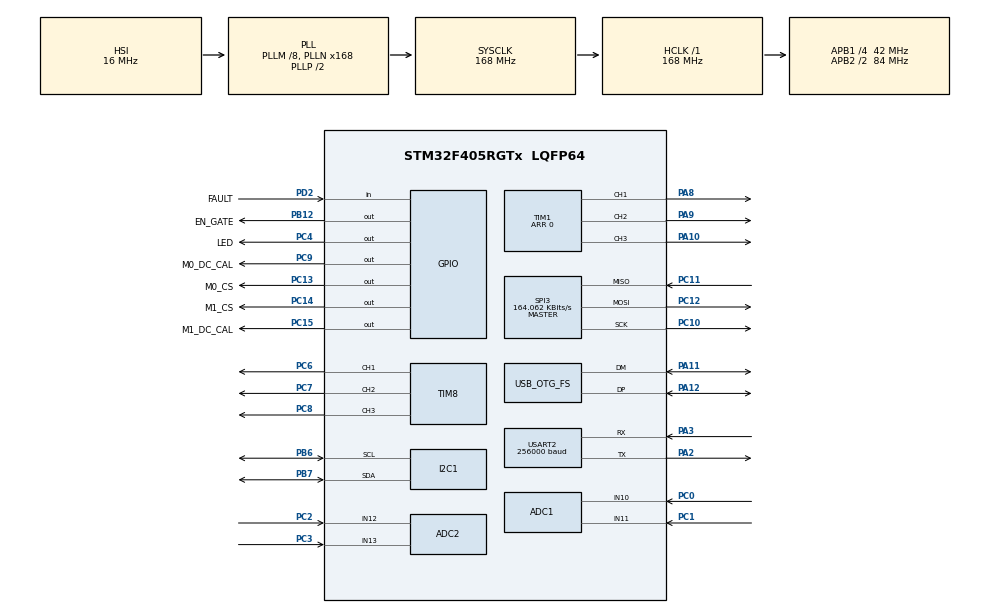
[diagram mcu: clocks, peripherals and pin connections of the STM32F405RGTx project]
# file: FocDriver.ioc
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ADC1.Channel-0\#ChannelRegularConversion=ADC_CHANNEL_10
ADC1.Channel-1\#ChannelInjectedConversion=ADC_CHANNEL_10
ADC1.Channel-2\#ChannelInjectedConversion=ADC_CHANNEL_10
ADC1.Channel-3\#ChannelRegularConversion=ADC_CHANNEL_10
ADC1.ExternalTrigConv=ADC_EXTERNALTRIGCONV_T8_TRGO
ADC1.ExternalTrigInjecConv=ADC_EXTERNALTRIGINJECCONV_T8_CC4
ADC1.InjNumberOfConversion=2
ADC1.InjectedOffset-1\#ChannelInjectedConversion=0
ADC1.InjectedOffset-2\#ChannelInjectedConversion=0
ADC1.InjectedRank-1\#ChannelInjectedConversion=1
ADC1.InjectedRank-2\#ChannelInjectedConversion=2
ADC1.NbrOfConversion=2
ADC1.NbrOfConversionFlag=1
ADC1.Rank-0\#ChannelRegularConversion=1
ADC1.Rank-3\#ChannelRegularConversion=2
ADC1.SamplingTime-0\#ChannelRegularConversion=ADC_SAMPLETIME_3CYCLES
ADC1.SamplingTime-1\#ChannelInjectedConversion=ADC_SAMPLETIME_3CYCLES
ADC1.SamplingTime-2\#ChannelInjectedConversion=ADC_SAMPLETIME_3CYCLES
ADC1.SamplingTime-3\#ChannelRegularConversion=ADC_SAMPLETIME_3CYCLES
ADC1.master=1
ADC2.Channel-0\#ChannelRegularConversion=ADC_CHANNEL_13
ADC2.Channel-1\#ChannelRegularConversion=ADC_CHANNEL_12
ADC2.Channel-5\#ChannelInjectedConversion=ADC_CHANNEL_13
ADC2.Channel-6\#ChannelInjectedConversion=ADC_CHANNEL_12
ADC2.DiscontinuousConvMode=DISABLE
ADC2.ExternalTrigConv=ADC_EXTERNALTRIGCONV_T8_TRGO
ADC2.ExternalTrigInjecConv=ADC_EXTERNALTRIGINJECCONV_T8_CC4
ADC2.InjNumberOfConversion=2
ADC2.InjectedOffset-5\#ChannelInjectedConversion=0
ADC2.InjectedOffset-6\#ChannelInjectedConversion=0
ADC2.InjectedRank-5\#ChannelInjectedConversion=1
ADC2.InjectedRank-6\#ChannelInjectedConversion=2
ADC2.NbrOfConversion=2
ADC2.NbrOfConversionFlag=1
ADC2.Rank-0\#ChannelRegularConversion=1
ADC2.Rank-1\#ChannelRegularConversion=2
ADC2.SamplingTime-0\#ChannelRegularConversion=ADC_SAMPLETIME_3CYCLES
ADC2.SamplingTime-1\#ChannelRegularConversion=ADC_SAMPLETIME_3CYCLES
ADC2.SamplingTime-5\#ChannelInjectedConversion=ADC_SAMPLETIME_3CYCLES
ADC2.SamplingTime-6\#ChannelInjectedConversion=ADC_SAMPLETIME_3CYCLES
ADC2.ScanConvMode=ENABLE
Dma.ADC2.2.Direction=DMA_PERIPH_TO_MEMORY
Dma.ADC2.2.FIFOMode=DMA_FIFOMODE_DISABLE
Dma.ADC2.2.Instance=DMA2_Stream2
Dma.ADC2.2.MemDataAlignment=DMA_MDATAALIGN_HALFWORD
Dma.ADC2.2.MemInc=DMA_MINC_ENABLE
Dma.ADC2.2.Mode=DMA_NORMAL
Dma.ADC2.2.PeriphDataAlignment=DMA_PDATAALIGN_HALFWORD
Dma.ADC2.2.PeriphInc=DMA_PINC_DISABLE
Dma.ADC2.2.Priority=DMA_PRIORITY_LOW
Dma.Request0=USART2_TX
Dma.Request1=USART2_RX
Dma.Request2=ADC2
Dma.USART2_RX.1.Direction=DMA_PERIPH_TO_MEMORY
Dma.USART2_RX.1.FIFOMode=DMA_FIFOMODE_DISABLE
Dma.USART2_RX.1.Instance=DMA1_Stream5
Dma.USART2_RX.1.MemDataAlignment=DMA_MDATAALIGN_BYTE
Dma.USART2_RX.1.MemInc=DMA_MINC_ENABLE
Dma.USART2_RX.1.Mode=DMA_NORMAL
Dma.USART2_RX.1.PeriphDataAlignment=DMA_PDATAALIGN_BYTE
Dma.USART2_RX.1.PeriphInc=DMA_PINC_DISABLE
Dma.USART2_RX.1.Priority=DMA_PRIORITY_LOW
Dma.USART2_TX.0.Direction=DMA_MEMORY_TO_PERIPH
Dma.USART2_TX.0.FIFOMode=DMA_FIFOMODE_DISABLE
Dma.USART2_TX.0.Instance=DMA1_Stream6
Dma.USART2_TX.0.MemDataAlignment=DMA_MDATAALIGN_BYTE
Dma.USART2_TX.0.MemInc=DMA_MINC_ENABLE
Dma.USART2_TX.0.Mode=DMA_NORMAL
Dma.USART2_TX.0.PeriphDataAlignment=DMA_PDATAALIGN_BYTE
Dma.USART2_TX.0.PeriphInc=DMA_PINC_DISABLE
Dma.USART2_TX.0.Priority=DMA_PRIORITY_LOW
I2C1.I2C_Mode=I2C_Fast
Mcu.Family=STM32F4
Mcu.Name=STM32F405RGTx
Mcu.Package=LQFP64
Mcu.UserConstants=TIM_PWM_FREQ,30000;TIM_CLK_MHZ,168
NVIC.ADC_IRQn=true\:0\:0\:false\:false\:true\:true\:true\:true
NVIC.DMA1_Stream5_IRQn=true\:0\:0\:false\:false\:true\:false\:true\:true
NVIC.DMA1_Stream6_IRQn=true\:0\:0\:false\:false\:true\:false\:true\:true
NVIC.DMA2_Stream2_IRQn=true\:0\:0\:false\:false\:true\:false\:true\:true
NVIC.OTG_FS_IRQn=true\:0\:0\:false\:false\:true\:false\:true\:true
NVIC.PriorityGroup=NVIC_PRIORITYGROUP_4
NVIC.TIM8_TRG_COM_TIM14_IRQn=true\:15\:0\:false\:false\:true\:false\:true\:true
NVIC.TimeBase=TIM8_TRG_COM_TIM14_IRQn
NVIC.TimeBaseIP=TIM14
NVIC.USART2_IRQn=true\:0\:0\:false\:false\:true\:true\:true\:true
PA10.Signal=S_TIM1_CH3
PA11.Mode=Device_Only
PA11.Signal=USB_OTG_FS_DM
PA12.Mode=Device_Only
PA12.Signal=USB_OTG_FS_DP
PA13.Mode=Serial_Wire
PA13.Signal=SYS_JTMS-SWDIO
PA14.Mode=Serial_Wire
PA14.Signal=SYS_JTCK-SWCLK
PA2.Mode=Asynchronous
PA2.Signal=USART2_TX
PA3.Mode=Asynchronous
PA3.Signal=USART2_RX
PA8.Signal=S_TIM1_CH1
PA9.Signal=S_TIM1_CH2
PB12.GPIO_Label=EN_GATE
PB12.Signal=GPIO_Output
PB6.Mode=I2C
PB6.Signal=I2C1_SCL
PB7.Mode=I2C
PB7.Signal=I2C1_SDA
PC0.Signal=ADCx_IN10
PC1.Signal=ADCx_IN11
PC10.Mode=Full_Duplex_Master
PC10.Signal=SPI3_SCK
PC11.Mode=Full_Duplex_Master
PC11.Signal=SPI3_MISO
PC12.Mode=Full_Duplex_Master
PC12.Signal=SPI3_MOSI
PC13-ANTI_TAMP.GPIO_Label=M0_CS
PC13-ANTI_TAMP.Signal=GPIO_Output
PC14-OSC32_IN.GPIO_Label=M1_CS
PC14-OSC32_IN.Signal=GPIO_Output
PC15-OSC32_OUT.GPIO_Label=M1_DC_CAL
PC15-OSC32_OUT.Signal=GPIO_Output
PC2.Signal=ADCx_IN12
PC3.Signal=ADCx_IN13
PC4.GPIO_Label=LED
PC4.PinState=GPIO_PIN_SET
PC4.Signal=GPIO_Output
PC6.Signal=S_TIM8_CH1
PC7.Signal=S_TIM8_CH2
PC8.Signal=S_TIM8_CH3
PC9.GPIO_Label=M0_DC_CAL
PC9.Signal=GPIO_Output
PD2.GPIO_Label=FAULT
PD2.GPIO_PuPd=GPIO_PULLUP
PD2.Signal=GPIO_Input
ProjectManager.HeapSize=0x400
ProjectManager.StackSize=0x400
ProjectManager.TargetToolchain=STM32CubeIDE
RCC.48MHZClocksFreq_Value=84000000
RCC.AHBFreq_Value=168000000
RCC.APB1CLKDivider=RCC_HCLK_DIV4
RCC.APB1Freq_Value=42000000
RCC.APB1TimFreq_Value=84000000
RCC.APB2CLKDivider=RCC_HCLK_DIV2
RCC.APB2Freq_Value=84000000
RCC.APB2TimFreq_Value=168000000
RCC.CortexFreq_Value=168000000
RCC.HCLKFreq_Value=168000000
RCC.HSE_VALUE=16000000
RCC.HSI_VALUE=16000000
RCC.LSE_VALUE=32768
RCC.PLLM=8
RCC.PLLN=168
RCC.PLLSourceVirtualString=RCC_PLLSOURCE_HSI
RCC.SYSCLKFreq_VALUE=168000000
RCC.SYSCLKSource=RCC_SYSCLKSOURCE_PLLCLK
RCC.VCOOutputFreq_Value=336000000
SH.ADCx_IN10.0=ADC1_IN10,IN10
SH.ADCx_IN11.0=ADC1_IN11,IN11
SH.ADCx_IN12.0=ADC2_IN12,IN12
SH.ADCx_IN13.0=ADC2_IN13,IN13
SH.S_TIM1_CH1.0=TIM1_CH1,PWM Generation1 CH1
SH.S_TIM1_CH2.0=TIM1_CH2,PWM Generation2 CH2
SH.S_TIM1_CH3.0=TIM1_CH3,PWM Generation3 CH3
SH.S_TIM8_CH1.0=TIM8_CH1,PWM Generation1 CH1
SH.S_TIM8_CH2.0=TIM8_CH2,PWM Generation2 CH2
SH.S_TIM8_CH3.0=TIM8_CH3,PWM Generation3 CH3
SPI3.BaudRatePrescaler=SPI_BAUDRATEPRESCALER_256
SPI3.CLKPhase=SPI_PHASE_2EDGE
SPI3.CalculateBaudRate=164.062 KBits/s
SPI3.DataSize=SPI_DATASIZE_16BIT
SPI3.Direction=SPI_DIRECTION_2LINES
SPI3.Mode=SPI_MODE_MASTER
SPI3.VirtualType=VM_MASTER
TIM1.AutoReloadPreload=TIM_AUTORELOAD_PRELOAD_ENABLE
TIM1.Channel-PWM\ Generation1\ CH1=TIM_CHANNEL_1
TIM1.Channel-PWM\ Generation2\ CH2=TIM_CHANNEL_2
TIM1.Channel-PWM\ Generation3\ CH3=TIM_CHANNEL_3
TIM1.CounterMode=TIM_COUNTERMODE_CENTERALIGNED1
TIM1.Period=0
TIM1.TIM_MasterOutputTrigger=TIM_TRGO_UPDATE
TIM8.AutoReloadPreload=TIM_AUTORELOAD_PRELOAD_ENABLE
TIM8.Channel-PWM\ Generation1\ CH1=TIM_CHANNEL_1
TIM8.Channel-PWM\ Generation2\ CH2=TIM_CHANNEL_2
TIM8.Channel-PWM\ Generation3\ CH3=TIM_CHANNEL_3
TIM8.Channel-PWM\ Generation4\ No\ Output=TIM_CHANNEL_4
TIM8.CounterMode=TIM_COUNTERMODE_CENTERALIGNED1
TIM8.OCMode_PWM-PWM\ Generation4\ No\ Output=TIM_OCMODE_PWM2
TIM8.OCPolarity_4=TIM_OCPOLARITY_HIGH
TIM8.Period=TIM_CLK_MHZ * 1000000 / TIM_PWM_FREQ / 2
TIM8.TIM_MasterOutputTrigger=TIM_TRGO_UPDATE
USART2.BaudRate=256000
USART2.VirtualMode=VM_ASYNC
USB_DEVICE.CLASS_NAME_FS=CDC
USB_DEVICE.VirtualMode-CDC_FS=Cdc
USB_DEVICE.VirtualModeFS=Cdc_FS
USB_OTG_FS.VirtualMode=Device_Only
VP_SYS_VS_tim14.Mode=TIM14
VP_TIM8_VS_no_output4.Mode=PWM Generation4 No Output
VP_USB_DEVICE_VS_USB_DEVICE_CDC_FS.Mode=CDC_FS
board=custom

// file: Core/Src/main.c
/* USER CODE BEGIN Header */
/**
  ******************************************************************************
  * @file           : main.c
  * @brief          : Main program body
  ******************************************************************************
  * @attention
  *
  * Copyright (c) 2023 STMicroelectronics.
  * All rights reserved.
  *
  * This software is licensed under terms that can be found in the LICENSE file
  * in the root directory of this software component.
  * If no LICENSE file comes with this software, it is provided AS-IS.
  *
  ******************************************************************************
  */
/* USER CODE END Header */
#include "main.h"
#include "adc.h"
#include "dma.h"
#include "i2c.h"
#include "spi.h"
#include "tim.h"
#include "usart.h"
#include "gpio.h"

/* USER CODE BEGIN Includes */
#include "common_inc.h"
#include "stdio.h"
/* USER CODE END Includes */

void SystemClock_Config(void);

/* USER CODE BEGIN 0 */
//ccmram char test[1024];
/* USER CODE END 0 */

int main(void)
{
  /* USER CODE BEGIN 1 */
//  for (int i = 0; i < sizeof(test); ++i, test[i] = 0);
  /* USER CODE END 1 */

  /* MCU Configuration--------------------------------------------------------*/

  /* Reset of all peripherals, Initializes the Flash interface and the Systick. */
  HAL_Init();

  /* Configure the system clock */
  SystemClock_Config();

  /* Initialize all configured peripherals */
  MX_GPIO_Init();
  MX_DMA_Init();
  MX_USART2_UART_Init();
  MX_SPI3_Init();
  MX_TIM1_Init();
  MX_I2C1_Init();
  MX_TIM8_Init();
  MX_ADC1_Init();
  MX_ADC2_Init();
  /* USER CODE BEGIN 2 */
  Main();
  /* USER CODE END 2 */

  /* Infinite loop */
    while (1) {

    }
}

void SystemClock_Config(void)
{
  RCC_OscInitTypeDef RCC_OscInitStruct = {0};
  RCC_ClkInitTypeDef RCC_ClkInitStruct = {0};

  /** Configure the main internal regulator output voltage
  */
  __HAL_RCC_PWR_CLK_ENABLE();
  __HAL_PWR_VOLTAGESCALING_CONFIG(PWR_REGULATOR_VOLTAGE_SCALE1);

  /** Initializes the RCC Oscillators according to the specified parameters
  * in the RCC_OscInitTypeDef structure.
  */
  RCC_OscInitStruct.OscillatorType = RCC_OSCILLATORTYPE_HSI;
  RCC_OscInitStruct.HSIState = RCC_HSI_ON;
  RCC_OscInitStruct.HSICalibrationValue = RCC_HSICALIBRATION_DEFAULT;
  RCC_OscInitStruct.PLL.PLLState = RCC_PLL_ON;
  RCC_OscInitStruct.PLL.PLLSource = RCC_PLLSOURCE_HSI;
  RCC_OscInitStruct.PLL.PLLM = 8;
  RCC_OscInitStruct.PLL.PLLN = 168;
  RCC_OscInitStruct.PLL.PLLP = RCC_PLLP_DIV2;
  RCC_OscInitStruct.PLL.PLLQ = 4;
  if (HAL_RCC_OscConfig(&RCC_OscInitStruct) != HAL_OK)
  {
    Error_Handler();
  }

  /** Initializes the CPU, AHB and APB buses clocks
  */
  RCC_ClkInitStruct.ClockType = RCC_CLOCKTYPE_HCLK|RCC_CLOCKTYPE_SYSCLK
                              |RCC_CLOCKTYPE_PCLK1|RCC_CLOCKTYPE_PCLK2;
  RCC_ClkInitStruct.SYSCLKSource = RCC_SYSCLKSOURCE_PLLCLK;
  RCC_ClkInitStruct.AHBCLKDivider = RCC_SYSCLK_DIV1;
  RCC_ClkInitStruct.APB1CLKDivider = RCC_HCLK_DIV4;
  RCC_ClkInitStruct.APB2CLKDivider = RCC_HCLK_DIV2;

  if (HAL_RCC_ClockConfig(&RCC_ClkInitStruct, FLASH_LATENCY_5) != HAL_OK)
  {
    Error_Handler();
  }
}

void HAL_TIM_PeriodElapsedCallback(TIM_HandleTypeDef *htim)
{
  if (htim->Instance == TIM14) {
    HAL_IncTick();
  }
}

void Error_Handler(void)
{
  /* USER CODE BEGIN Error_Handler_Debug */
    /* User can add his own implementation to report the HAL error return state */
//    __disable_irq();
//    while (1) {
//    }
  /* USER CODE END Error_Handler_Debug */
}
